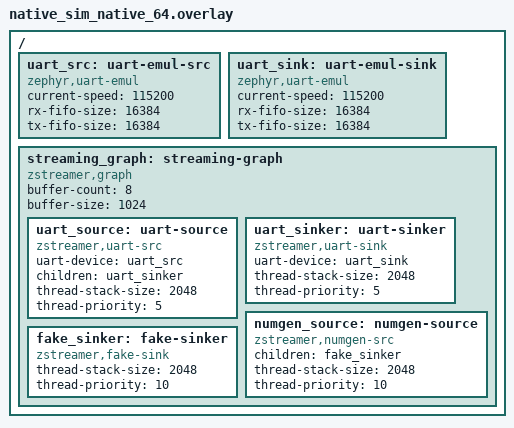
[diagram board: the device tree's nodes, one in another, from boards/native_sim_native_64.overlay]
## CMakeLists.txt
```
# Copyright (c) 2026 sharonthecreator
# SPDX-License-Identifier: Apache-2.0

cmake_minimum_required(VERSION 3.20.0)
find_package(Zephyr REQUIRED HINTS $ENV{ZEPHYR_BASE})
project(zstreamer_node_test)

target_include_directories(app PRIVATE ../../include)
target_sources(app PRIVATE src/main.c)
```

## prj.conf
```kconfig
# Copyright (c) 2026 sharonthecreator
# SPDX-License-Identifier: Apache-2.0

CONFIG_ZTEST=y
CONFIG_ZSTREAMER=y
CONFIG_ZSTREAMER_TEST_NUMGEN_SRC=y
CONFIG_ZSTREAMER_TEST_PASSTHROUGH_NODE=y
CONFIG_ZSTREAMER_TEST_COUNT_SINK=y
CONFIG_NET_BUF_POOL_USAGE=y
CONFIG_LOG=y
```

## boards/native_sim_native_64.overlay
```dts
/*
 * Copyright (c) 2026 sharonthecreator
 * SPDX-License-Identifier: Apache-2.0
 */

/ {
	uart_src: uart-emul-src {
		compatible = "zephyr,uart-emul";
		current-speed = <115200>;
		rx-fifo-size = <16384>;
		tx-fifo-size = <16384>;
		status = "okay";
	};

	uart_sink: uart-emul-sink {
		compatible = "zephyr,uart-emul";
		current-speed = <115200>;
		rx-fifo-size = <16384>;
		tx-fifo-size = <16384>;
		status = "okay";
	};

	streaming_graph: streaming-graph {
		compatible = "zstreamer,graph";
		buffer-count = <8>;
		buffer-size = <1024>;

		uart_source: uart-source {
			compatible = "zstreamer,uart-src";
			uart-device = <&uart_src>;
			children = <&uart_sinker>;
			thread-stack-size = <2048>;
			thread-priority = <5>;
		};

		uart_sinker: uart-sinker {
			compatible = "zstreamer,uart-sink";
			uart-device = <&uart_sink>;
			thread-stack-size = <2048>;
			thread-priority = <5>;
		};

		numgen_source: numgen-source {
			compatible = "zstreamer,numgen-src";
			children = <&fake_sinker>;
			thread-stack-size = <2048>;
			thread-priority = <10>;
		};

		fake_sinker: fake-sinker {
			compatible = "zstreamer,fake-sink";
			thread-stack-size = <2048>;
			thread-priority = <10>;
		};
	};
};
```

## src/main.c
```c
/*
 * Copyright (c) 2026 sharonthecreator
 * SPDX-License-Identifier: Apache-2.0
 */

#include <zephyr/device.h>
#include <zephyr/net_buf.h>
#include <zephyr/ztest.h>

#include <zstreamer/node.h>
#include <zstreamer/source.h>

#include "count_sink.h"

#define GRAPH_NODE DT_NODELABEL(streaming_graph)
#define SRC_NODE DT_NODELABEL(numgen_source)
#define PROC_NODE DT_NODELABEL(passthrough)
#define SINK_NODE DT_NODELABEL(count_sinker)

static const struct device *graph_dev = DEVICE_DT_GET(GRAPH_NODE);
static const struct device *src_dev = DEVICE_DT_GET(SRC_NODE);
static const struct device *proc_dev = DEVICE_DT_GET(PROC_NODE);
static const struct device *sink_dev = DEVICE_DT_GET(SINK_NODE);

static void cleanup(void *fixture) {
  ARG_UNUSED(fixture);

  zstreamer_source_stop(src_dev);
  count_sink_reset(sink_dev);
}

ZTEST_SUITE(zstreamer_processor, NULL, NULL, cleanup, cleanup, NULL);

ZTEST(zstreamer_processor, test_devices_ready) {
  zassert_true(device_is_ready(graph_dev), "graph not ready");
  zassert_true(device_is_ready(src_dev), "src not ready");
  zassert_true(device_is_ready(proc_dev), "processor not ready");
  zassert_true(device_is_ready(sink_dev), "sink not ready");
}

ZTEST(zstreamer_processor, test_pipeline_flow) {
  int ret;
  uint32_t bufs;

  ret = zstreamer_source_start(src_dev);
  zassert_equal(ret, 0, "src start: %d", ret);

  k_msleep(200);

  ret = zstreamer_source_stop(src_dev);
  zassert_equal(ret, 0, "src stop: %d", ret);

  bufs = count_sink_get_buf_count(sink_dev);
  zassert_true(bufs > 0, "no buffers through processor, got %u", bufs);
}

ZTEST(zstreamer_processor, test_processor_restart_cycle) {
  for (int cycle = 0; cycle < 5; cycle++) {
    int ret;
    uint32_t bufs;

    count_sink_reset(sink_dev);

    ret = zstreamer_source_start(src_dev);
    zassert_equal(ret, 0, "cycle %d start: %d", cycle, ret);

    k_msleep(100);

    ret = zstreamer_source_stop(src_dev);
    zassert_equal(ret, 0, "cycle %d stop: %d", cycle, ret);

    bufs = count_sink_get_buf_count(sink_dev);
    zassert_true(bufs > 0, "cycle %d: no buffers", cycle);
  }
}

ZTEST(zstreamer_processor, test_processor_high_throughput) {
  int ret;
  uint32_t bufs;

  ret = zstreamer_source_start(src_dev);
  zassert_equal(ret, 0, "src start: %d", ret);

  k_msleep(5000);

  ret = zstreamer_source_stop(src_dev);
  zassert_equal(ret, 0, "src stop: %d", ret);

  bufs = count_sink_get_buf_count(sink_dev);
  zassert_true(bufs >= 100,
               "expected >= 100 bufs through processor, got %u", bufs);
}

ZTEST(zstreamer_processor, test_processor_sustained_restart) {
  uint32_t total_bufs = 0;

  for (int cycle = 0; cycle < 30; cycle++) {
    int ret;

    count_sink_reset(sink_dev);

    ret = zstreamer_source_start(src_dev);
    zassert_equal(ret, 0, "cycle %d start: %d", cycle, ret);

    k_msleep(50);

    ret = zstreamer_source_stop(src_dev);
    zassert_equal(ret, 0, "cycle %d stop: %d", cycle, ret);

    total_bufs += count_sink_get_buf_count(sink_dev);
  }

  zassert_true(total_bufs >= 30,
               "expected >= 30 total bufs across 30 cycles, got %u",
               total_bufs);
}
```
